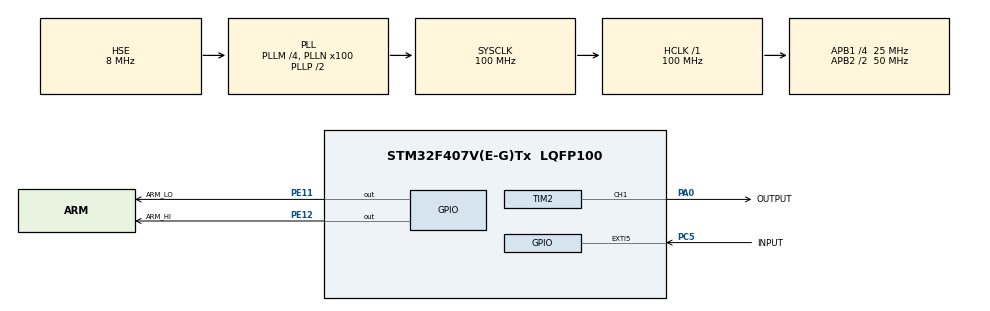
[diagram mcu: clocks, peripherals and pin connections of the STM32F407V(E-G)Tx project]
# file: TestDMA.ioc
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Dma.Request0=TIM1_CH4/TRIG/COM
Dma.TIM1_CH4/TRIG/COM.0.Direction=DMA_MEMORY_TO_PERIPH
Dma.TIM1_CH4/TRIG/COM.0.FIFOMode=DMA_FIFOMODE_DISABLE
Dma.TIM1_CH4/TRIG/COM.0.Instance=DMA2_Stream4
Dma.TIM1_CH4/TRIG/COM.0.MemDataAlignment=DMA_MDATAALIGN_WORD
Dma.TIM1_CH4/TRIG/COM.0.MemInc=DMA_MINC_ENABLE
Dma.TIM1_CH4/TRIG/COM.0.Mode=DMA_NORMAL
Dma.TIM1_CH4/TRIG/COM.0.PeriphDataAlignment=DMA_PDATAALIGN_WORD
Dma.TIM1_CH4/TRIG/COM.0.PeriphInc=DMA_PINC_DISABLE
Dma.TIM1_CH4/TRIG/COM.0.Priority=DMA_PRIORITY_VERY_HIGH
Mcu.Family=STM32F4
Mcu.Name=STM32F407V(E-G)Tx
Mcu.Package=LQFP100
NVIC.DMA2_Stream4_IRQn=true\:0\:0\:false\:false\:true\:false\:true\:true
NVIC.EXTI9_5_IRQn=true\:0\:0\:false\:false\:true\:true\:true\:true
NVIC.PriorityGroup=NVIC_PRIORITYGROUP_4
NVIC.TIM3_IRQn=true\:15\:0\:false\:false\:true\:false\:true\:true
NVIC.TimeBase=TIM3_IRQn
NVIC.TimeBaseIP=TIM3
PA0-WKUP.GPIO_Label=OUTPUT
PA0-WKUP.Signal=S_TIM2_CH1_ETR
PA13.Mode=Serial_Wire
PA13.Signal=SYS_JTMS-SWDIO
PA14.Mode=Serial_Wire
PA14.Signal=SYS_JTCK-SWCLK
PC14-OSC32_IN.Mode=LSE-External-Oscillator
PC14-OSC32_IN.Signal=RCC_OSC32_IN
PC15-OSC32_OUT.Mode=LSE-External-Oscillator
PC15-OSC32_OUT.Signal=RCC_OSC32_OUT
PC5.GPIO_Label=INPUT
PC5.Signal=GPXTI5
PE11.GPIO_Label=ARM_LO
PE11.GPIO_Speed=GPIO_SPEED_FREQ_VERY_HIGH
PE11.Signal=GPIO_Output
PE12.GPIO_Label=ARM_HI
PE12.GPIO_Speed=GPIO_SPEED_FREQ_VERY_HIGH
PE12.Signal=GPIO_Output
PH0-OSC_IN.Mode=HSE-External-Oscillator
PH0-OSC_IN.Signal=RCC_OSC_IN
PH1-OSC_OUT.Mode=HSE-External-Oscillator
PH1-OSC_OUT.Signal=RCC_OSC_OUT
ProjectManager.HeapSize=0x200
ProjectManager.StackSize=0x400
ProjectManager.TargetToolchain=STM32CubeIDE
RCC.48MHZClocksFreq_Value=50000000
RCC.AHBFreq_Value=100000000
RCC.APB1CLKDivider=RCC_HCLK_DIV4
RCC.APB1Freq_Value=25000000
RCC.APB1TimFreq_Value=50000000
RCC.APB2CLKDivider=RCC_HCLK_DIV2
RCC.APB2Freq_Value=50000000
RCC.APB2TimFreq_Value=100000000
RCC.CortexFreq_Value=100000000
RCC.HCLKFreq_Value=100000000
RCC.HSE_VALUE=8000000
RCC.HSI_VALUE=16000000
RCC.PLLM=4
RCC.PLLN=100
RCC.PLLSourceVirtual=RCC_PLLSOURCE_HSE
RCC.SYSCLKFreq_VALUE=100000000
RCC.SYSCLKSource=RCC_SYSCLKSOURCE_PLLCLK
RCC.VCOOutputFreq_Value=200000000
SH.S_TIM2_CH1_ETR.0=TIM2_CH1,PWM Generation1 CH1
TIM1.AutoReloadPreload=TIM_AUTORELOAD_PRELOAD_DISABLE
TIM1.Channel-PWM\ Generation4\ No\ Output=TIM_CHANNEL_4
TIM1.Period=10-1
TIM1.Pulse-PWM\ Generation4\ No\ Output=1
TIM1.TIM_MasterOutputTrigger=TIM_TRGO_RESET
TIM2.Channel-PWM\ Generation1\ CH1=TIM_CHANNEL_1
TIM2.Period=200-1
TIM2.Prescaler=500-1
TIM2.Pulse-PWM\ Generation1\ CH1=1
VP_SYS_VS_tim3.Mode=TIM3
VP_TIM1_VS_ClockSourceINT.Mode=Internal
VP_TIM1_VS_no_output4.Mode=PWM Generation4 No Output
VP_TIM2_VS_ClockSourceINT.Mode=Internal
board=custom

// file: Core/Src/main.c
/* USER CODE BEGIN Header */
/**
  ******************************************************************************
  * @file           : main.c
  * @brief          : Main program body
  ******************************************************************************
  * @attention
  *
  * Copyright (c) 2024 STMicroelectronics.
  * All rights reserved.
  *
  * This software is licensed under terms that can be found in the LICENSE file
  * in the root directory of this software component.
  * If no LICENSE file comes with this software, it is provided AS-IS.
  *
  ******************************************************************************
  */
/* USER CODE END Header */
#include "main.h"
#include "dma.h"
#include "tim.h"
#include "gpio.h"

/* USER CODE BEGIN Includes */
#include "pulse.h"
/* USER CODE END Includes */

void SystemClock_Config(void);

int main(void)
{

  /* MCU Configuration--------------------------------------------------------*/

  /* Reset of all peripherals, Initializes the Flash interface and the Systick. */
  HAL_Init();

  /* Configure the system clock */
  SystemClock_Config();

  /* Initialize all configured peripherals */
  MX_GPIO_Init();
  MX_DMA_Init();
  MX_TIM1_Init();
  MX_TIM2_Init();
  /* USER CODE BEGIN 2 */

  // Инициализация данных DMA
  Data_Init ();

  // Запуск таймера синхронизации канала DMA для передачи данных
  if (HAL_TIM_PWM_Start(&htim1, TIM_CHANNEL_4) != HAL_OK)
  {
	  Error_Handler();
  }

  // Таймер 2 выдаёт короткий сигнал, который коммутирется на PC4
  // И запускает передачу по DMA
  if (HAL_TIM_PWM_Start(&htim2, TIM_CHANNEL_1) != HAL_OK)
  {
	  Error_Handler();
  }

  /* USER CODE END 2 */

  /* Infinite loop */
  while (1)
  {

  }
}

void SystemClock_Config(void)
{
  RCC_OscInitTypeDef RCC_OscInitStruct = {0};
  RCC_ClkInitTypeDef RCC_ClkInitStruct = {0};

  /** Configure the main internal regulator output voltage
  */
  __HAL_RCC_PWR_CLK_ENABLE();
  __HAL_PWR_VOLTAGESCALING_CONFIG(PWR_REGULATOR_VOLTAGE_SCALE1);

  /** Initializes the RCC Oscillators according to the specified parameters
  * in the RCC_OscInitTypeDef structure.
  */
  RCC_OscInitStruct.OscillatorType = RCC_OSCILLATORTYPE_HSE;
  RCC_OscInitStruct.HSEState = RCC_HSE_ON;
  RCC_OscInitStruct.PLL.PLLState = RCC_PLL_ON;
  RCC_OscInitStruct.PLL.PLLSource = RCC_PLLSOURCE_HSE;
  RCC_OscInitStruct.PLL.PLLM = 4;
  RCC_OscInitStruct.PLL.PLLN = 100;
  RCC_OscInitStruct.PLL.PLLP = RCC_PLLP_DIV2;
  RCC_OscInitStruct.PLL.PLLQ = 4;
  if (HAL_RCC_OscConfig(&RCC_OscInitStruct) != HAL_OK)
  {
    Error_Handler();
  }

  /** Initializes the CPU, AHB and APB buses clocks
  */
  RCC_ClkInitStruct.ClockType = RCC_CLOCKTYPE_HCLK|RCC_CLOCKTYPE_SYSCLK
                              |RCC_CLOCKTYPE_PCLK1|RCC_CLOCKTYPE_PCLK2;
  RCC_ClkInitStruct.SYSCLKSource = RCC_SYSCLKSOURCE_PLLCLK;
  RCC_ClkInitStruct.AHBCLKDivider = RCC_SYSCLK_DIV1;
  RCC_ClkInitStruct.APB1CLKDivider = RCC_HCLK_DIV4;
  RCC_ClkInitStruct.APB2CLKDivider = RCC_HCLK_DIV2;

  if (HAL_RCC_ClockConfig(&RCC_ClkInitStruct, FLASH_LATENCY_3) != HAL_OK)
  {
    Error_Handler();
  }
}

/* USER CODE BEGIN 4 */
/* @brief Обратный вызов INPUT_Pin запускает передачу DMA по входному сигналу
 * Задержка 4 мкс
 *
 */
void HAL_GPIO_EXTI_Callback(uint16_t GPIO_Pin)
{
  if(GPIO_Pin == INPUT_Pin) {
	Start_DMA_Transfer();
  }
}

/* USER CODE END 4 */

void HAL_TIM_PeriodElapsedCallback(TIM_HandleTypeDef *htim)
{
  if (htim->Instance == TIM3) {
    HAL_IncTick();
  }
}

void Error_Handler(void)
{
  __disable_irq();
  while (1)
  {
  }
}
